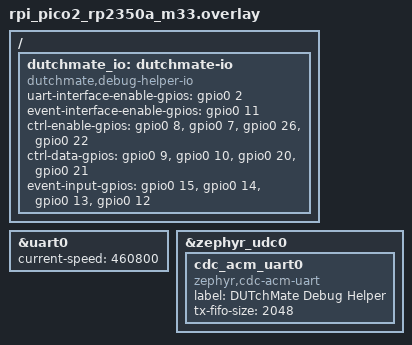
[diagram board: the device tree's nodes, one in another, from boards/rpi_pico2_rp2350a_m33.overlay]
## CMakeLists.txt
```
cmake_minimum_required(VERSION 3.20.0)

find_package(Zephyr REQUIRED HINTS $ENV{ZEPHYR_BASE})

set(DUTCHMATE_MINIMUM_ZEPHYR_VERSION "4.4.2")
set(DUTCHMATE_ZEPHYR_VERSION
    "${KERNEL_VERSION_MAJOR}.${KERNEL_VERSION_MINOR}.${KERNEL_PATCHLEVEL}"
)
if("${DUTCHMATE_ZEPHYR_VERSION}" VERSION_LESS
   "${DUTCHMATE_MINIMUM_ZEPHYR_VERSION}")
    message(FATAL_ERROR
        "DUTchMate RP2350 Debug Helper requires Zephyr "
        "${DUTCHMATE_MINIMUM_ZEPHYR_VERSION} or newer because earlier "
        "PL011 drivers do not acknowledge UART error interrupts "
        "(GHSA-36rp-2hcp-f5hv)."
    )
endif()

project(dutchmate_rp2350_debug_helper)

target_sources(app PRIVATE
    src/cdc_tx.c
    src/cdc_tx_state.c
    src/command_decode.c
    src/command_executor.c
    src/command_ingress.c
    src/command_runtime.c
    src/command_response.c
    src/connection_epoch.c
    src/control_state.c
    src/hello.c
    src/main.c
    src/ndjson_framer.c
    src/output_drain.c
    src/platform_io.c
    src/telemetry.c
    src/uart_event.c
    src/uart_rx.c
    src/uart_rx_ring.c
    src/uart_tx.c
    src/uart_tx_state.c
    src/usb_connection.c
)

target_sources_ifdef(CONFIG_DUTCHMATE_STACK_PROBE app PRIVATE
    src/stack_probe.c
)
```

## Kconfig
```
mainmenu "DUTchMate RP2350 Debug Helper"

source "Kconfig.zephyr"

config DUTCHMATE_RP2350_DEBUG_HELPER
	bool
	default y
	select PICOSDK_USE_CLAIM
	select PICOSDK_USE_TIMER

menu "DUTchMate identity"

config DUTCHMATE_FIRMWARE_VERSION
	string "Firmware product version reported by hello"
	default "development"
	help
	  Release builds use the Semantic Version from the firmware project's
	  PRODUCT_VERSION file. Development and diagnostic builds may use a 1..64 byte
	  identifier with ASCII letters, digits, dot, underscore, plus, or hyphen.

config DUTCHMATE_PRODUCTION_BUILD
	bool "Enforce production USB identity"
	help
	  Reject a build that still uses the development VID/PID pair. Production
	  builds must provide an assigned pair through CDC_ACM_SERIAL_VID and
	  CDC_ACM_SERIAL_PID.

endmenu

config DUTCHMATE_STACK_PROBE
	bool "Expose post-epoch stack high-water measurements in hello"
	depends on THREAD_ANALYZER && THREAD_NAME
	help
	  Diagnostic build only. After an epoch ends, the next hello messages
	  carry one measured thread or ISR stack each in the firmware identifier.
	  The production protocol and UART evidence remain unchanged.
```

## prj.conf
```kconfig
CONFIG_GPIO=y
CONFIG_SERIAL=y
CONFIG_UART_INTERRUPT_DRIVEN=y
CONFIG_UART_USE_RUNTIME_CONFIGURE=y

CONFIG_USB_DEVICE_STACK_NEXT=y
CONFIG_USBD_CDC_ACM_CLASS=y
CONFIG_UART_LINE_CTRL=y
CONFIG_CDC_ACM_SERIAL_INITIALIZE_AT_BOOT=y
CONFIG_CDC_ACM_SERIAL_ENABLE_AT_BOOT=y
CONFIG_CDC_ACM_SERIAL_VID=0x2E8A
CONFIG_CDC_ACM_SERIAL_PID=0x000A
CONFIG_CDC_ACM_SERIAL_MANUFACTURER_STRING="DUTchMate"
CONFIG_CDC_ACM_SERIAL_PRODUCT_STRING="Debug Helper"

CONFIG_HWINFO=y

# No console may share the future DUT UART or USB CDC transport.
CONFIG_CONSOLE=n
CONFIG_UART_CONSOLE=n
CONFIG_PRINTK=n
CONFIG_LOG=n
CONFIG_BOOT_BANNER=n

CONFIG_MINIMAL_LIBC=y
CONFIG_MAIN_STACK_SIZE=2048
CONFIG_MAIN_THREAD_PRIORITY=5
CONFIG_DUTCHMATE_FIRMWARE_VERSION="development"
```

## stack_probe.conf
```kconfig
# Opt-in USB-only runtime stack measurement image. Do not use for production.
CONFIG_THREAD_ANALYZER=y
CONFIG_THREAD_NAME=y
CONFIG_THREAD_RUNTIME_STATS=n
CONFIG_DUTCHMATE_STACK_PROBE=y
CONFIG_DUTCHMATE_FIRMWARE_VERSION="stackprobe-1"
```

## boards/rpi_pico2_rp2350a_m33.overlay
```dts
#include <zephyr/dt-bindings/gpio/gpio.h>

/ {
	dutchmate_io: dutchmate-io {
		compatible = "dutchmate,debug-helper-io";

		uart-interface-enable-gpios = <&gpio0 2 GPIO_ACTIVE_HIGH>;
		event-interface-enable-gpios = <&gpio0 11 GPIO_ACTIVE_HIGH>;

		ctrl-enable-gpios = <&gpio0 8 GPIO_ACTIVE_HIGH>,
				    <&gpio0 7 GPIO_ACTIVE_HIGH>,
				    <&gpio0 26 GPIO_ACTIVE_HIGH>,
				    <&gpio0 22 GPIO_ACTIVE_HIGH>;
		ctrl-data-gpios = <&gpio0 9 GPIO_ACTIVE_HIGH>,
				  <&gpio0 10 GPIO_ACTIVE_HIGH>,
				  <&gpio0 20 GPIO_ACTIVE_HIGH>,
				  <&gpio0 21 GPIO_ACTIVE_HIGH>;
		event-input-gpios = <&gpio0 15 GPIO_ACTIVE_HIGH>,
				    <&gpio0 14 GPIO_ACTIVE_HIGH>,
				    <&gpio0 13 GPIO_ACTIVE_HIGH>,
				    <&gpio0 12 GPIO_ACTIVE_HIGH>;
	};
};

&uart0 {
	current-speed = <460800>;
	status = "okay";
};

&zephyr_udc0 {
	cdc_acm_uart0: cdc_acm_uart0 {
		compatible = "zephyr,cdc-acm-uart";
		label = "DUTchMate Debug Helper";
		tx-fifo-size = <2048>;
	};
};
```

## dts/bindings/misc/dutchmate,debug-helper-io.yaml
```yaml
description: DUTchMate Revision A Debug Helper GPIO assignment

compatible: "dutchmate,debug-helper-io"

properties:
  uart-interface-enable-gpios:
    type: phandle-array
    required: true
    description: Active-high TXU0202 interface enable

  event-interface-enable-gpios:
    type: phandle-array
    required: true
    description: Active-high TXU0104 event interface enable

  ctrl-enable-gpios:
    type: phandle-array
    required: true
    description: Active-high CTRL0 through CTRL3 output enables

  ctrl-data-gpios:
    type: phandle-array
    required: true
    description: CTRL0 through CTRL3 data outputs

  event-input-gpios:
    type: phandle-array
    required: true
    description: EVENT0 through EVENT3 inputs
```

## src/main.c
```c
#include "platform_io.h"
#include "uart_rx.h"
#include "uart_tx.h"
#include "usb_connection.h"

#include <zephyr/kernel.h>

int main(void)
{
	if (IS_ENABLED(CONFIG_DUTCHMATE_STACK_PROBE)) {
		(void)k_thread_name_set(k_current_get(), "main");
	}
	int result = dutchmate_platform_io_initialize_safe();

	if (result != 0) {
		return result;
	}
	result = dutchmate_uart_rx_initialize();
	if (result != 0) {
		(void)dutchmate_platform_io_force_safe();
		return result;
	}
	result = dutchmate_uart_tx_initialize();
	if (result != 0) {
		(void)dutchmate_platform_io_force_safe();
		return result;
	}

	return dutchmate_usb_connection_run();
}
```

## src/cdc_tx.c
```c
#include "cdc_tx.h"

#include "command_runtime.h"

#include <errno.h>

#include <hardware/timer.h>
#include <zephyr/device.h>
#include <zephyr/drivers/uart.h>
#include <zephyr/kernel.h>
#include <zephyr/sys/atomic.h>

#define DUTCHMATE_CDC_TX_NO_PROGRESS_TIMEOUT_US 250000ULL

static const struct device *cdc;
static struct dmh_cdc_tx tx;
static struct k_spinlock tx_lock;
static atomic_t initialized;

static int write_bytes(void *context, const uint8_t *data, size_t length)
{
	const struct device *device = context;

	return uart_fifo_fill(device, data, (int)length);
}

static void stop_writes(void *context)
{
	const struct device *device = context;

	uart_irq_tx_disable(device);
}

static void cdc_callback(
	const struct device *device,
	void *user_data
)
{
	k_spinlock_key_t key;

	ARG_UNUSED(user_data);
	key = k_spin_lock(&tx_lock);
	if (device != cdc || uart_irq_update(device) <= 0) {
		dmh_cdc_tx_driver_fault(&tx);
	} else {
		while (uart_irq_is_pending(device) > 0) {
			if (uart_irq_rx_ready(device) > 0 &&
			    !dutchmate_command_runtime_on_cdc_rx_ready(device)) {
				break;
			}
			if (uart_irq_tx_ready(device) > 0) {
				dmh_cdc_tx_on_writable(&tx, time_us_64());
			}
			if (uart_irq_update(device) <= 0) {
				dmh_cdc_tx_driver_fault(&tx);
				break;
			}
		}
	}
	k_spin_unlock(&tx_lock, key);
}

int dutchmate_cdc_tx_initialize(const struct device *cdc_device)
{
	const struct dmh_cdc_tx_port port = {
		.context = (void *)cdc_device,
		.write = write_bytes,
		.stop = stop_writes,
	};
	int result;

	if (cdc_device == NULL || !device_is_ready(cdc_device) ||
	    !atomic_cas(&initialized, 0, 1)) {
		return -EINVAL;
	}
	cdc = cdc_device;
	dmh_cdc_tx_init(&tx, &port);
	result = uart_irq_callback_user_data_set(cdc, cdc_callback, NULL);
	if (result != 0) {
		atomic_clear(&initialized);
		cdc = NULL;
		return result;
	}
	return 0;
}

enum dmh_cdc_tx_result dutchmate_cdc_tx_start(
	const uint8_t *frame,
	size_t length
)
{
	enum dmh_cdc_tx_result result;
	k_spinlock_key_t key;

	if (atomic_get(&initialized) == 0) {
		return DMH_CDC_TX_HARDWARE_FAULT;
	}
	key = k_spin_lock(&tx_lock);
	result = dmh_cdc_tx_start(
		&tx,
		frame,
		length,
		time_us_64(),
		DUTCHMATE_CDC_TX_NO_PROGRESS_TIMEOUT_US
	);
	k_spin_unlock(&tx_lock, key);
	if (result == DMH_CDC_TX_PENDING) {
		uart_irq_tx_enable(cdc);
	}
	return result;
}

enum dmh_cdc_tx_result dutchmate_cdc_tx_poll(void)
{
	enum dmh_cdc_tx_result result;
	k_spinlock_key_t key;

	key = k_spin_lock(&tx_lock);
	result = dmh_cdc_tx_poll(&tx, time_us_64());
	k_spin_unlock(&tx_lock, key);
	return result;
}

void dutchmate_cdc_tx_cancel(void)
{
	k_spinlock_key_t key;

	if (atomic_get(&initialized) == 0) {
		return;
	}
	key = k_spin_lock(&tx_lock);
	dmh_cdc_tx_cancel(&tx);
	k_spin_unlock(&tx_lock, key);
}
```

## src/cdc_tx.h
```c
#ifndef DUTCHMATE_CDC_TX_H
#define DUTCHMATE_CDC_TX_H

#include "cdc_tx_state.h"

#include <stddef.h>
#include <stdint.h>

struct device;

int dutchmate_cdc_tx_initialize(const struct device *cdc_device);
enum dmh_cdc_tx_result dutchmate_cdc_tx_start(
	const uint8_t *frame,
	size_t length
);
enum dmh_cdc_tx_result dutchmate_cdc_tx_poll(void);
void dutchmate_cdc_tx_cancel(void);

#endif
```

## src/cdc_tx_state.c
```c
#include "cdc_tx_state.h"

#include <string.h>

static void finish(
	struct dmh_cdc_tx *tx,
	enum dmh_cdc_tx_result result
)
{
	tx->port.stop(tx->port.context);
	tx->state = result;
}

void dmh_cdc_tx_init(
	struct dmh_cdc_tx *tx,
	const struct dmh_cdc_tx_port *port
)
{
	tx->port = *port;
	tx->length = 0U;
	tx->accepted = 0U;
	tx->last_progress_us = 0U;
	tx->timeout_us = 0U;
	tx->state = DMH_CDC_TX_IDLE;
}

enum dmh_cdc_tx_result dmh_cdc_tx_start(
	struct dmh_cdc_tx *tx,
	const uint8_t *frame,
	size_t length,
	uint64_t now_us,
	uint64_t timeout_us
)
{
	if (frame == NULL || length == 0U || length > DMH_CDC_TX_MAX_FRAME_BYTES ||
	    timeout_us == 0U) {
		return DMH_CDC_TX_INVALID_ARGUMENT;
	}
	if (tx->state != DMH_CDC_TX_IDLE) {
		return DMH_CDC_TX_BUSY;
	}
	(void)memcpy(tx->frame, frame, length);
	tx->length = length;
	tx->accepted = 0U;
	tx->last_progress_us = now_us;
	tx->timeout_us = timeout_us;
	tx->state = DMH_CDC_TX_PENDING;
	return DMH_CDC_TX_PENDING;
}

void dmh_cdc_tx_on_writable(struct dmh_cdc_tx *tx, uint64_t now_us)
{
	size_t remaining;
	int written;

	if (tx->state != DMH_CDC_TX_PENDING) {
		tx->port.stop(tx->port.context);
		return;
	}
	remaining = tx->length - tx->accepted;
	written = tx->port.write(
		tx->port.context,
		&tx->frame[tx->accepted],
		remaining
	);
	if (written <= 0 || (size_t)written > remaining) {
		finish(tx, DMH_CDC_TX_HARDWARE_FAULT);
		return;
	}
	tx->accepted += (size_t)written;
	tx->last_progress_us = now_us;
	if (tx->accepted == tx->length) {
		finish(tx, DMH_CDC_TX_COMPLETED);
	}
}

void dmh_cdc_tx_driver_fault(struct dmh_cdc_tx *tx)
{
	if (tx->state == DMH_CDC_TX_PENDING) {
		finish(tx, DMH_CDC_TX_HARDWARE_FAULT);
	}
}

void dmh_cdc_tx_cancel(struct dmh_cdc_tx *tx)
{
	if (tx->state == DMH_CDC_TX_PENDING) {
		tx->port.stop(tx->port.context);
	}
	tx->length = 0U;
	tx->accepted = 0U;
	tx->last_progress_us = 0U;
	tx->timeout_us = 0U;
	tx->state = DMH_CDC_TX_IDLE;
}

enum dmh_cdc_tx_result dmh_cdc_tx_poll(
	struct dmh_cdc_tx *tx,
	uint64_t now_us
)
{
	enum dmh_cdc_tx_result result;

	if (tx->state == DMH_CDC_TX_PENDING &&
	    now_us - tx->last_progress_us >= tx->timeout_us) {
		finish(tx, DMH_CDC_TX_TIMEOUT);
	}
	result = tx->state;
	if (result == DMH_CDC_TX_COMPLETED ||
	    result == DMH_CDC_TX_TIMEOUT ||
	    result == DMH_CDC_TX_HARDWARE_FAULT) {
		tx->length = 0U;
		tx->accepted = 0U;
		tx->last_progress_us = 0U;
		tx->timeout_us = 0U;
		tx->state = DMH_CDC_TX_IDLE;
	}
	return result;
}
```

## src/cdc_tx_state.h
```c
#ifndef DUTCHMATE_CDC_TX_STATE_H
#define DUTCHMATE_CDC_TX_STATE_H

#include <stddef.h>
#include <stdint.h>

#define DMH_CDC_TX_MAX_FRAME_BYTES 1536U

enum dmh_cdc_tx_result {
	DMH_CDC_TX_IDLE = 0,
	DMH_CDC_TX_PENDING,
	DMH_CDC_TX_COMPLETED,
	DMH_CDC_TX_INVALID_ARGUMENT,
	DMH_CDC_TX_BUSY,
	DMH_CDC_TX_TIMEOUT,
	DMH_CDC_TX_HARDWARE_FAULT,
};

struct dmh_cdc_tx_port {
	void *context;
	int (*write)(void *context, const uint8_t *data, size_t length);
	void (*stop)(void *context);
};

struct dmh_cdc_tx {
	struct dmh_cdc_tx_port port;
	uint8_t frame[DMH_CDC_TX_MAX_FRAME_BYTES];
	size_t length;
	size_t accepted;
	uint64_t last_progress_us;
	uint64_t timeout_us;
	enum dmh_cdc_tx_result state;
};

void dmh_cdc_tx_init(
	struct dmh_cdc_tx *tx,
	const struct dmh_cdc_tx_port *port
);
enum dmh_cdc_tx_result dmh_cdc_tx_start(
	struct dmh_cdc_tx *tx,
	const uint8_t *frame,
	size_t length,
	uint64_t now_us,
	uint64_t timeout_us
);
void dmh_cdc_tx_on_writable(struct dmh_cdc_tx *tx, uint64_t now_us);
void dmh_cdc_tx_driver_fault(struct dmh_cdc_tx *tx);
void dmh_cdc_tx_cancel(struct dmh_cdc_tx *tx);
enum dmh_cdc_tx_result dmh_cdc_tx_poll(
	struct dmh_cdc_tx *tx,
	uint64_t now_us
);

#endif
```

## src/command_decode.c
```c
#include "command_decode.h"

#include <errno.h>
#include <limits.h>
#include <string.h>

#define DMH_COMMAND_FRAME_MAX_BODY_BYTES 2047U
#define DMH_COMMAND_NAME_MAX_BYTES 23U
#define DMH_BASE64_MAX_BYTES 1368U

enum field_id {
	FIELD_CMD = 0,
	FIELD_CHANNEL,
	FIELD_MODE,
	FIELD_ACTIVE_LEVEL,
	FIELD_IDLE_LEVEL,
	FIELD_PULSE_MS,
	FIELD_STATE,
	FIELD_DATA_B64,
	FIELD_COUNT,
};

enum string_parse_result {
	STRING_PARSE_OK = 0,
	STRING_PARSE_SYNTAX,
	STRING_PARSE_LIMIT,
};

struct parser {
	const uint8_t *data;
	size_t length;
	size_t index;
};

struct raw_fields {
	uint32_t present;
	char cmd[DMH_COMMAND_NAME_MAX_BYTES + 1U];
	char channel[6];
	char mode[11];
	char active_level[5];
	char idle_level[5];
	char state[7];
	char data_b64[DMH_BASE64_MAX_BYTES + 1U];
	uint32_t pulse_ms;
};

static void skip_whitespace(struct parser *parser)
{
	while (parser->index < parser->length &&
	       (parser->data[parser->index] == ' ' ||
		parser->data[parser->index] == '\t')) {
		parser->index++;
	}
}

static int hex_value(uint8_t byte)
{
	if (byte >= '0' && byte <= '9') {
		return byte - '0';
	}
	if (byte >= 'a' && byte <= 'f') {
		return byte - 'a' + 10;
	}
	if (byte >= 'A' && byte <= 'F') {
		return byte - 'A' + 10;
	}
	return -1;
}

static enum string_parse_result append_string_byte(
	char *output,
	size_t output_capacity,
	size_t *output_length,
	uint8_t byte
)
{
	if (byte == 0U || *output_length + 1U >= output_capacity) {
		return STRING_PARSE_LIMIT;
	}
	output[*output_length] = (char)byte;
	(*output_length)++;
	return STRING_PARSE_OK;
}

static enum string_parse_result parse_unicode_escape(
	struct parser *parser,
	char *output,
	size_t output_capacity,
	size_t *output_length
)
{
	unsigned int codepoint = 0U;
	size_t count;

	if (parser->length - parser->index < 4U) {
		return STRING_PARSE_SYNTAX;
	}
	for (count = 0U; count < 4U; count++) {
		int digit = hex_value(parser->data[parser->index++]);

		if (digit < 0) {
			return STRING_PARSE_SYNTAX;
		}
		codepoint = (codepoint << 4U) | (unsigned int)digit;
	}
	if (codepoint > 0x7FU) {
		return STRING_PARSE_LIMIT;
	}
	return append_string_byte(
		output,
		output_capacity,
		output_length,
		(uint8_t)codepoint
	);
}

static enum string_parse_result parse_json_string(
	struct parser *parser,
	char *output,
	size_t output_capacity
)
{
	size_t output_length = 0U;

	if (parser->index >= parser->length || parser->data[parser->index] != '"') {
		return STRING_PARSE_SYNTAX;
	}
	parser->index++;
	while (parser->index < parser->length) {
		uint8_t byte = parser->data[parser->index++];
		enum string_parse_result result;

		if (byte == '"') {
			output[output_length] = '\0';
			return STRING_PARSE_OK;
		}
		if (byte < 0x20U || byte >= 0x80U) {
			return STRING_PARSE_SYNTAX;
		}
		if (byte != '\\') {
			result = append_string_byte(
				output, output_capacity, &output_length, byte
			);
		} else {
			if (parser->index >= parser->length) {
				return STRING_PARSE_SYNTAX;
			}
			byte = parser->data[parser->index++];
			if (byte == 'u') {
				result = parse_unicode_escape(
					parser,
					output,
					output_capacity,
					&output_length
				);
			} else {
				switch (byte) {
				case '"':
				case '\\':
				case '/':
					break;
				case 'b':
					byte = '\b';
					break;
				case 'f':
					byte = '\f';
					break;
				case 'n':
					byte = '\n';
					break;
				case 'r':
					byte = '\r';
					break;
				case 't':
					byte = '\t';
					break;
				default:
					return STRING_PARSE_SYNTAX;
				}
				result = append_string_byte(
					output, output_capacity, &output_length, byte
				);
			}
		}
		if (result != STRING_PARSE_OK) {
			return result;
		}
	}
	return STRING_PARSE_SYNTAX;
}

static int field_id_from_name(const char *name)
{
	static const char *const names[] = {
		[FIELD_CMD] = "cmd",
		[FIELD_CHANNEL] = "channel",
		[FIELD_MODE] = "mode",
		[FIELD_ACTIVE_LEVEL] = "active_level",
		[FIELD_IDLE_LEVEL] = "idle_level",
		[FIELD_PULSE_MS] = "pulse_ms",
		[FIELD_STATE] = "state",
		[FIELD_DATA_B64] = "data_b64",
	};
	size_t index;

	for (index = 0U; index < FIELD_COUNT; index++) {
		if (strcmp(name, names[index]) == 0) {
			return (int)index;
		}
	}
	return -1;
}

static enum string_parse_result parse_field_string(
	struct parser *parser,
	struct raw_fields *fields,
	enum field_id field
)
{
	switch (field) {
	case FIELD_CMD:
		return parse_json_string(parser, fields->cmd, sizeof(fields->cmd));
	case FIELD_CHANNEL:
		return parse_json_string(
			parser, fields->channel, sizeof(fields->channel)
		);
	case FIELD_MODE:
		return parse_json_string(parser, fields->mode, sizeof(fields->mode));
	case FIELD_ACTIVE_LEVEL:
		return parse_json_string(
			parser, fields->active_level, sizeof(fields->active_level)
		);
	case FIELD_IDLE_LEVEL:
		return parse_json_string(
			parser, fields->idle_level, sizeof(fields->idle_level)
		);
	case FIELD_STATE:
		return parse_json_string(parser, fields->state, sizeof(fields->state));
	case FIELD_DATA_B64:
		return parse_json_string(
			parser, fields->data_b64, sizeof(fields->data_b64)
		);
	case FIELD_PULSE_MS:
	case FIELD_COUNT:
		return STRING_PARSE_SYNTAX;
	}
	return STRING_PARSE_SYNTAX;
}

static bool parse_pulse_ms(struct parser *parser, uint32_t *value)
{
	uint32_t parsed = 0U;
	size_t start = parser->index;

	if (start >= parser->length || parser->data[start] < '0' ||
	    parser->data[start] > '9') {
		return false;
	}
	if (parser->data[start] == '0' && start + 1U < parser->length &&
	    parser->data[start + 1U] >= '0' && parser->data[start + 1U] <= '9') {
		return false;
	}
	while (parser->index < parser->length &&
	       parser->data[parser->index] >= '0' &&
	       parser->data[parser->index] <= '9') {
		uint32_t digit = parser->data[parser->index] - '0';

		if (parsed > (UINT32_MAX - digit) / 10U) {
			return false;
		}
		parsed = parsed * 10U + digit;
		parser->index++;
	}
	*value = parsed;
	return true;
}

static int parse_object(
	const uint8_t *frame,
	size_t frame_length,
	struct raw_fields *fields,
	enum dmh_command_decode_failure *failure
)
{
	struct parser parser = {
		.data = frame,
		.length = frame_length,
		.index = 1U,
	};

	if (frame_length < 2U || frame[0] != '{' || frame[frame_length - 1U] != '}') {
		*failure = DMH_COMMAND_DECODE_INVALID_COMMAND;
		return -EINVAL;
	}
	for (;;) {
		char key[17];
		enum string_parse_result string_result;
		int field_number;
		enum field_id field;

		skip_whitespace(&parser);
		if (parser.index >= parser.length) {
			*failure = DMH_COMMAND_DECODE_INVALID_COMMAND;
			return -EINVAL;
		}
		if (parser.data[parser.index] == '}') {
			parser.index++;
			break;
		}
		string_result = parse_json_string(&parser, key, sizeof(key));
		if (string_result != STRING_PARSE_OK) {
			*failure = string_result == STRING_PARSE_LIMIT ?
				DMH_COMMAND_DECODE_INVALID_ARGUMENT :
				DMH_COMMAND_DECODE_INVALID_COMMAND;
			return -EINVAL;
		}
		field_number = field_id_from_name(key);
		if (field_number < 0) {
			*failure = DMH_COMMAND_DECODE_INVALID_ARGUMENT;
			return -EINVAL;
		}
		field = (enum field_id)field_number;
		if ((fields->present & (1U << field)) != 0U) {
			*failure = DMH_COMMAND_DECODE_INVALID_ARGUMENT;
			return -EINVAL;
		}
		skip_whitespace(&parser);
		if (parser.index >= parser.length || parser.data[parser.index] != ':') {
			*failure = DMH_COMMAND_DECODE_INVALID_COMMAND;
			return -EINVAL;
		}
		parser.index++;
		skip_whitespace(&parser);
		if (field == FIELD_PULSE_MS) {
			if (!parse_pulse_ms(&parser, &fields->pulse_ms)) {
				*failure = DMH_COMMAND_DECODE_INVALID_ARGUMENT;
				return -EINVAL;
			}
		} else {
			if (parser.index >= parser.length ||
			    parser.data[parser.index] != '"') {
				*failure = field == FIELD_CMD ?
					DMH_COMMAND_DECODE_INVALID_COMMAND :
					DMH_COMMAND_DECODE_INVALID_ARGUMENT;
				return -EINVAL;
			}
			string_result = parse_field_string(&parser, fields, field);
			if (string_result != STRING_PARSE_OK) {
				*failure = string_result == STRING_PARSE_SYNTAX ?
					DMH_COMMAND_DECODE_INVALID_COMMAND :
					DMH_COMMAND_DECODE_INVALID_ARGUMENT;
				return -EINVAL;
			}
		}
		fields->present |= 1U << field;
		skip_whitespace(&parser);
		if (parser.index >= parser.length) {
			*failure = DMH_COMMAND_DECODE_INVALID_COMMAND;
			return -EINVAL;
		}
		if (parser.data[parser.index] == '}') {
			parser.index++;
			break;
		}
		if (parser.data[parser.index] != ',') {
			*failure = DMH_COMMAND_DECODE_INVALID_COMMAND;
			return -EINVAL;
		}
		parser.index++;
		skip_whitespace(&parser);
		if (parser.index >= parser.length || parser.data[parser.index] == '}') {
			*failure = DMH_COMMAND_DECODE_INVALID_COMMAND;
			return -EINVAL;
		}
	}
	if (parser.index != parser.length) {
		*failure = DMH_COMMAND_DECODE_INVALID_COMMAND;
		return -EINVAL;
	}
	return 0;
}

static bool decode_channel(const char *value, uint8_t *channel)
{
	if (strlen(value) != 5U || memcmp(value, "CTRL", 4U) != 0 ||
	    value[4] < '0' || value[4] > '3') {
		return false;
	}
	*channel = (uint8_t)(value[4] - '0');
	return true;
}

static bool decode_level(const char *value, enum dmh_control_level *level)
{
	if (strcmp(value, "low") == 0) {
		*level = DMH_CONTROL_LEVEL_LOW;
		return true;
	}
	if (strcmp(value, "high") == 0) {
		*level = DMH_CONTROL_LEVEL_HIGH;
		return true;
	}
	return false;
}

static int base64_value(char byte)
{
	if (byte >= 'A' && byte <= 'Z') {
		return byte - 'A';
	}
	if (byte >= 'a' && byte <= 'z') {
		return byte - 'a' + 26;
	}
	if (byte >= '0' && byte <= '9') {
		return byte - '0' + 52;
	}
	if (byte == '+') {
		return 62;
	}
	if (byte == '/') {
		return 63;
	}
	return -1;
}

static bool decode_base64(const char *encoded, struct dmh_uart_send_command *uart)
{
	size_t encoded_length = strlen(encoded);
	size_t input_index;
	size_t output_index = 0U;

	if (encoded_length < 4U || encoded_length > DMH_BASE64_MAX_BYTES ||
	    encoded_length % 4U != 0U) {
		return false;
	}
	for (input_index = 0U; input_index < encoded_length; input_index += 4U) {
		int first = base64_value(encoded[input_index]);
		int second = base64_value(encoded[input_index + 1U]);
		int third;
		int fourth;
		bool last = input_index + 4U == encoded_length;

		if (first < 0 || second < 0 || output_index >= sizeof(uart->data)) {
			return false;
		}
		uart->data[output_index++] =
			(uint8_t)(((unsigned int)first << 2U) |
				 ((unsigned int)second >> 4U));
		if (encoded[input_index + 2U] == '=') {
			if (!last || encoded[input_index + 3U] != '=') {
				return false;
			}
			continue;
		}
		third = base64_value(encoded[input_index + 2U]);
		if (third < 0 || output_index >= sizeof(uart->data)) {
			return false;
		}
		uart->data[output_index++] =
			(uint8_t)(((unsigned int)second << 4U) |
				 ((unsigned int)third >> 2U));
		if (encoded[input_index + 3U] == '=') {
			if (!last) {
				return false;
			}
			continue;
		}
		fourth = base64_value(encoded[input_index + 3U]);
		if (fourth < 0 || output_index >= sizeof(uart->data)) {
			return false;
		}
		uart->data[output_index++] =
			(uint8_t)(((unsigned int)third << 6U) | (unsigned int)fourth);
	}
	uart->length = output_index;
	return output_index > 0U;
}

static bool exact_fields(uint32_t actual, uint32_t required)
{
	return actual == required;
}

static bool decode_configure(
	const struct raw_fields *fields,
	struct dmh_command *command
)
{
	uint32_t required = (1U << FIELD_CMD) | (1U << FIELD_CHANNEL) |
			    (1U << FIELD_MODE) | (1U << FIELD_ACTIVE_LEVEL);
	struct dmh_configure_command *configure = &command->value.configure;

	if (!decode_channel(fields->channel, &command->channel) ||
	    !decode_level(fields->active_level, &configure->active_level)) {
		return false;
	}
	if (strcmp(fields->mode, "open_drain") == 0) {
		if (!exact_fields(fields->present, required) ||
		    configure->active_level != DMH_CONTROL_LEVEL_LOW) {
			return false;
		}
		configure->mode = DMH_CONTROL_MODE_OPEN_DRAIN;
		configure->has_idle_level = false;
	} else if (strcmp(fields->mode, "push_pull") == 0) {
		required |= 1U << FIELD_IDLE_LEVEL;
		if (!exact_fields(fields->present, required) ||
		    !decode_level(fields->idle_level, &configure->idle_level) ||
		    configure->active_level == configure->idle_level) {
			return false;
		}
		configure->mode = DMH_CONTROL_MODE_PUSH_PULL;
		configure->has_idle_level = true;
	} else {
		return false;
	}
	command->kind = DMH_COMMAND_CONFIGURE_GPIO_MODE;
	return true;
}

static bool decode_pulse(
	const struct raw_fields *fields,
	struct dmh_command *command
)
{
	uint32_t required = (1U << FIELD_CMD) | (1U << FIELD_CHANNEL) |
			    (1U << FIELD_PULSE_MS);

	if (!exact_fields(fields->present, required) || fields->pulse_ms < 1U ||
	    fields->pulse_ms > 10000U ||
	    !decode_channel(fields->channel, &command->channel)) {
		return false;
	}
	command->kind = DMH_COMMAND_PULSE_CONTROL;
	command->value.pulse_ms = fields->pulse_ms;
	return true;
}

static bool decode_state(
	const struct raw_fields *fields,
	struct dmh_command *command
)
{
	uint32_t required = (1U << FIELD_CMD) | (1U << FIELD_CHANNEL) |
			    (1U << FIELD_STATE);

	if (!exact_fields(fields->present, required) ||
	    !decode_channel(fields->channel, &command->channel)) {
		return false;
	}
	if (strcmp(fields->state, "active") == 0) {
		command->value.control_state = DMH_CONTROL_STATE_ACTIVE;
	} else if (strcmp(fields->state, "idle") == 0) {
		command->value.control_state = DMH_CONTROL_STATE_IDLE;
	} else {
		return false;
	}
	command->kind = DMH_COMMAND_SET_CONTROL_STATE;
	return true;
}

static bool decode_uart_send(
	const struct raw_fields *fields,
	struct dmh_command *command
)
{
	uint32_t required = (1U << FIELD_CMD) | (1U << FIELD_DATA_B64);

	if (!exact_fields(fields->present, required) ||
	    !decode_base64(fields->data_b64, &command->value.uart_send)) {
		return false;
	}
	command->kind = DMH_COMMAND_UART_SEND;
	return true;
}

int dmh_command_decode(
	const uint8_t *frame,
	size_t frame_length,
	struct dmh_command *command,
	enum dmh_command_decode_failure *failure
)
{
	struct raw_fields fields = {0};
	bool valid;

	if ((frame == NULL && frame_length > 0U) || command == NULL ||
	    failure == NULL) {
		return -EINVAL;
	}
	memset(command, 0, sizeof(*command));
	if (frame_length == 0U || frame_length > DMH_COMMAND_FRAME_MAX_BODY_BYTES ||
	    parse_object(frame, frame_length, &fields, failure) != 0) {
		if (frame_length == 0U || frame_length > DMH_COMMAND_FRAME_MAX_BODY_BYTES) {
			*failure = DMH_COMMAND_DECODE_INVALID_COMMAND;
		}
		return -EINVAL;
	}
	if ((fields.present & (1U << FIELD_CMD)) == 0U || fields.cmd[0] == '\0') {
		*failure = DMH_COMMAND_DECODE_INVALID_COMMAND;
		return -EINVAL;
	}
	if (strcmp(fields.cmd, "configure_gpio_mode") == 0) {
		valid = decode_configure(&fields, command);
	} else if (strcmp(fields.cmd, "pulse_control") == 0) {
		valid = decode_pulse(&fields, command);
	} else if (strcmp(fields.cmd, "set_control_state") == 0) {
		valid = decode_state(&fields, command);
	} else if (strcmp(fields.cmd, "uart_send") == 0) {
		valid = decode_uart_send(&fields, command);
	} else {
		*failure = DMH_COMMAND_DECODE_INVALID_COMMAND;
		return -EINVAL;
	}
	if (!valid) {
		memset(command, 0, sizeof(*command));
		*failure = DMH_COMMAND_DECODE_INVALID_ARGUMENT;
		return -EINVAL;
	}
	return 0;
}
```

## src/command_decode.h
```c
#ifndef DUTCHMATE_COMMAND_DECODE_H
#define DUTCHMATE_COMMAND_DECODE_H

#include "control_types.h"
#include "uart_limits.h"

#include <stdbool.h>
#include <stddef.h>
#include <stdint.h>

enum dmh_command_kind {
	DMH_COMMAND_NONE = 0,
	DMH_COMMAND_CONFIGURE_GPIO_MODE,
	DMH_COMMAND_PULSE_CONTROL,
	DMH_COMMAND_SET_CONTROL_STATE,
	DMH_COMMAND_UART_SEND,
};

enum dmh_command_decode_failure {
	DMH_COMMAND_DECODE_INVALID_COMMAND = 0,
	DMH_COMMAND_DECODE_INVALID_ARGUMENT,
};

struct dmh_configure_command {
	enum dmh_control_mode mode;
	enum dmh_control_level active_level;
	enum dmh_control_level idle_level;
	bool has_idle_level;
};

struct dmh_uart_send_command {
	uint8_t data[DMH_UART_SEND_MAX_BYTES];
	size_t length;
};

struct dmh_command {
	enum dmh_command_kind kind;
	uint8_t channel;
	union {
		struct dmh_configure_command configure;
		uint32_t pulse_ms;
		enum dmh_control_state control_state;
		struct dmh_uart_send_command uart_send;
	} value;
};

int dmh_command_decode(
	const uint8_t *frame,
	size_t frame_length,
	struct dmh_command *command,
	enum dmh_command_decode_failure *failure
);

#endif
```

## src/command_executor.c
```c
#include "command_executor.h"

#include <string.h>

static const char invalid_command_detail[] = "Command is invalid";
static const char invalid_argument_detail[] = "Command argument is invalid";
static const char control_fault_detail[] = "Control hardware operation failed";
static const char uart_fault_detail[] = "UART transmission failed";
static const char uart_timeout_detail[] = "UART transmission timed out";

static enum dmh_command_executor_result response_encoded(
	struct dmh_command_executor *executor,
	int encode_result
)
{
	if (encode_result != 0) {
		executor->state = DMH_COMMAND_EXECUTOR_STATE_IDLE;
		executor->response_length = 0U;
		return DMH_COMMAND_EXECUTOR_INTERNAL_FAULT;
	}
	executor->state = DMH_COMMAND_EXECUTOR_STATE_RESPONSE;
	return DMH_COMMAND_EXECUTOR_RESPONSE_READY;
}

static enum dmh_command_executor_result stage_timestamp(
	struct dmh_command_executor *executor,
	uint64_t timestamp_us
)
{
	return response_encoded(
		executor,
		dmh_timestamp_response_encode(
			timestamp_us,
			executor->response,
			sizeof(executor->response),
			&executor->response_length
		)
	);
}

static enum dmh_command_executor_result stage_uart_success(
	struct dmh_command_executor *executor,
	uint64_t timestamp_us,
	size_t bytes_accepted
)
{
	return response_encoded(
		executor,
		dmh_uart_send_response_encode(
			timestamp_us,
			bytes_accepted,
			executor->response,
			sizeof(executor->response),
			&executor->response_length
		)
	);
}

static enum dmh_command_executor_result stage_error(
	struct dmh_command_executor *executor,
	enum dmh_command_error_code code,
	const char *detail,
	size_t detail_length
)
{
	return response_encoded(
		executor,
		dmh_error_response_encode(
			code,
			detail,
			detail_length,
			executor->response,
			sizeof(executor->response),
			&executor->response_length
		)
	);
}

static enum dmh_command_executor_result stage_literal_error(
	struct dmh_command_executor *executor,
	enum dmh_command_error_code code,
	const char *detail
)
{
	return stage_error(executor, code, detail, strlen(detail));
}

static enum dmh_command_executor_result stage_not_configured(
	struct dmh_command_executor *executor,
	uint8_t channel
)
{
	char detail[] = "CTRL0 is not configured";

	detail[4] = (char)('0' + channel);
	return stage_error(
		executor,
		DMH_COMMAND_ERROR_NOT_CONFIGURED,
		detail,
		sizeof(detail) - 1U
	);
}

static enum dmh_command_executor_result map_control_result(
	struct dmh_command_executor *executor,
	enum dmh_control_result result,
	uint8_t channel,
	uint64_t timestamp_us
)
{
	if (result == DMH_CONTROL_OK) {
		return stage_timestamp(executor, timestamp_us);
	}
	if (result == DMH_CONTROL_INVALID_ARGUMENT) {
		return stage_literal_error(
			executor,
			DMH_COMMAND_ERROR_INVALID_ARGUMENT,
			invalid_argument_detail
		);
	}
	if (result == DMH_CONTROL_NOT_CONFIGURED) {
		return stage_not_configured(executor, channel);
	}
	return stage_literal_error(
		executor,
		DMH_COMMAND_ERROR_HARDWARE_FAULT,
		control_fault_detail
	);
}

static enum dmh_command_executor_result submit_configure(
	struct dmh_command_executor *executor,
	const struct dmh_command *command,
	uint64_t now_us
)
{
	const struct dmh_configure_command *configuration = &command->value.configure;

	return map_control_result(
		executor,
		dmh_control_configure(
			executor->control,
			command->channel,
			configuration->mode,
			configuration->active_level,
			configuration->has_idle_level,
			configuration->idle_level
		),
		command->channel,
		now_us
	);
}

static enum dmh_command_executor_result submit_pulse(
	struct dmh_command_executor *executor,
	const struct dmh_command *command,
	uint64_t now_us
)
{
	enum dmh_control_result result = dmh_control_pulse_start(
		executor->control,
		command->channel,
		command->value.pulse_ms,
		now_us
	);

	if (result == DMH_CONTROL_PENDING) {
		executor->state = DMH_COMMAND_EXECUTOR_STATE_CONTROL_PULSE;
		return DMH_COMMAND_EXECUTOR_PENDING;
	}
	return map_control_result(executor, result, command->channel, now_us);
}

static enum dmh_command_executor_result submit_control_state(
	struct dmh_command_executor *executor,
	const struct dmh_command *command,
	uint64_t now_us
)
{
	return map_control_result(
		executor,
		dmh_control_set_state(
			executor->control,
			command->channel,
			command->value.control_state
		),
		command->channel,
		now_us
	);
}

static enum dmh_command_executor_result submit_uart(
	struct dmh_command_executor *executor,
	const struct dmh_command *command,
	uint64_t now_us
)
{
	enum dmh_uart_tx_result result = executor->uart.start(
		executor->uart.context,
		command->value.uart_send.data,
		command->value.uart_send.length,
		now_us
	);

	if (result == DMH_UART_TX_PENDING) {
		executor->state = DMH_COMMAND_EXECUTOR_STATE_UART_TX;
		return DMH_COMMAND_EXECUTOR_PENDING;
	}
	if (result == DMH_UART_TX_COMPLETED) {
		return stage_uart_success(
			executor,
			now_us,
			command->value.uart_send.length
		);
	}
	if (result == DMH_UART_TX_INVALID_ARGUMENT) {
		return stage_literal_error(
			executor,
			DMH_COMMAND_ERROR_INVALID_ARGUMENT,
			invalid_argument_detail
		);
	}
	return stage_literal_error(
		executor,
		DMH_COMMAND_ERROR_HARDWARE_FAULT,
		uart_fault_detail
	);
}

void dmh_command_executor_init(
	struct dmh_command_executor *executor,
	struct dmh_control *control,
	const struct dmh_command_uart_port *uart
)
{
	executor->control = control;
	executor->uart = *uart;
	executor->state = DMH_COMMAND_EXECUTOR_STATE_IDLE;
	executor->response_length = 0U;
}

enum dmh_command_executor_result dmh_command_executor_submit(
	struct dmh_command_executor *executor,
	const struct dmh_command *command,
	uint64_t now_us
)
{
	if (executor->state != DMH_COMMAND_EXECUTOR_STATE_IDLE) {
		return DMH_COMMAND_EXECUTOR_BUSY;
	}
	if (command->kind == DMH_COMMAND_CONFIGURE_GPIO_MODE) {
		return submit_configure(executor, command, now_us);
	}
	if (command->kind == DMH_COMMAND_PULSE_CONTROL) {
		return submit_pulse(executor, command, now_us);
	}
	if (command->kind == DMH_COMMAND_SET_CONTROL_STATE) {
		return submit_control_state(executor, command, now_us);
	}
	if (command->kind == DMH_COMMAND_UART_SEND) {
		return submit_uart(executor, command, now_us);
	}
	return stage_literal_error(
		executor,
		DMH_COMMAND_ERROR_INVALID_COMMAND,
		invalid_command_detail
	);
}

enum dmh_command_executor_result dmh_command_executor_reject(
	struct dmh_command_executor *executor,
	enum dmh_command_decode_failure failure
)
{
	if (executor->state != DMH_COMMAND_EXECUTOR_STATE_IDLE) {
		return DMH_COMMAND_EXECUTOR_BUSY;
	}
	if (failure == DMH_COMMAND_DECODE_INVALID_ARGUMENT) {
		return stage_literal_error(
			executor,
			DMH_COMMAND_ERROR_INVALID_ARGUMENT,
			invalid_argument_detail
		);
	}
	return stage_literal_error(
		executor,
		DMH_COMMAND_ERROR_INVALID_COMMAND,
		invalid_command_detail
	);
}

enum dmh_command_executor_result dmh_command_executor_poll(
	struct dmh_command_executor *executor,
	uint64_t now_us
)
{
	if (executor->state == DMH_COMMAND_EXECUTOR_STATE_CONTROL_PULSE) {
		enum dmh_control_poll_result result = dmh_control_poll(
			executor->control,
			now_us
		);

		if (result == DMH_CONTROL_POLL_COMPLETED) {
			return stage_timestamp(executor, now_us);
		}
		if (result == DMH_CONTROL_POLL_HARDWARE_FAULT) {
			return stage_literal_error(
				executor,
				DMH_COMMAND_ERROR_HARDWARE_FAULT,
				control_fault_detail
			);
		}
		return DMH_COMMAND_EXECUTOR_PENDING;
	}
	if (executor->state == DMH_COMMAND_EXECUTOR_STATE_UART_TX) {
		size_t bytes_accepted;
		enum dmh_uart_tx_result result = executor->uart.poll(
			executor->uart.context,
			now_us,
			&bytes_accepted
		);

		if (result == DMH_UART_TX_COMPLETED) {
			return stage_uart_success(executor, now_us, bytes_accepted);
		}
		if (result == DMH_UART_TX_TIMEOUT) {
			return stage_literal_error(
				executor,
				DMH_COMMAND_ERROR_TIMEOUT,
				uart_timeout_detail
			);
		}
		if (result == DMH_UART_TX_HARDWARE_FAULT) {
			return stage_literal_error(
				executor,
				DMH_COMMAND_ERROR_HARDWARE_FAULT,
				uart_fault_detail
			);
		}
		if (result != DMH_UART_TX_PENDING) {
			return DMH_COMMAND_EXECUTOR_INTERNAL_FAULT;
		}
		return DMH_COMMAND_EXECUTOR_PENDING;
	}
	if (executor->state == DMH_COMMAND_EXECUTOR_STATE_RESPONSE) {
		return DMH_COMMAND_EXECUTOR_RESPONSE_READY;
	}
	return DMH_COMMAND_EXECUTOR_IDLE;
}

const char *dmh_command_executor_response(
	const struct dmh_command_executor *executor,
	size_t *response_length
)
{
	if (executor->state != DMH_COMMAND_EXECUTOR_STATE_RESPONSE) {
		*response_length = 0U;
		return NULL;
	}
	*response_length = executor->response_length;
	return executor->response;
}

void dmh_command_executor_response_sent(struct dmh_command_executor *executor)
{
	if (executor->state == DMH_COMMAND_EXECUTOR_STATE_RESPONSE) {
		executor->response_length = 0U;
		executor->state = DMH_COMMAND_EXECUTOR_STATE_IDLE;
	}
}

enum dmh_control_result dmh_command_executor_cancel_epoch(
	struct dmh_command_executor *executor
)
{
	executor->uart.cancel(executor->uart.context);
	executor->state = DMH_COMMAND_EXECUTOR_STATE_IDLE;
	executor->response_length = 0U;
	return dmh_control_end_epoch(executor->control);
}
```

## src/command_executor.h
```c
#ifndef DUTCHMATE_COMMAND_EXECUTOR_H
#define DUTCHMATE_COMMAND_EXECUTOR_H

#include "command_decode.h"
#include "command_response.h"
#include "control_state.h"
#include "uart_tx_state.h"

#include <stddef.h>
#include <stdint.h>

enum dmh_command_executor_result {
	DMH_COMMAND_EXECUTOR_IDLE = 0,
	DMH_COMMAND_EXECUTOR_PENDING,
	DMH_COMMAND_EXECUTOR_RESPONSE_READY,
	DMH_COMMAND_EXECUTOR_BUSY,
	DMH_COMMAND_EXECUTOR_INTERNAL_FAULT,
};

struct dmh_command_uart_port {
	void *context;
	enum dmh_uart_tx_result (*start)(
		void *context,
		const uint8_t *data,
		size_t length,
		uint64_t now_us
	);
	enum dmh_uart_tx_result (*poll)(
		void *context,
		uint64_t now_us,
		size_t *bytes_accepted
	);
	void (*cancel)(void *context);
};

enum dmh_command_executor_state {
	DMH_COMMAND_EXECUTOR_STATE_IDLE = 0,
	DMH_COMMAND_EXECUTOR_STATE_CONTROL_PULSE,
	DMH_COMMAND_EXECUTOR_STATE_UART_TX,
	DMH_COMMAND_EXECUTOR_STATE_RESPONSE,
};

struct dmh_command_executor {
	struct dmh_control *control;
	struct dmh_command_uart_port uart;
	enum dmh_command_executor_state state;
	char response[DMH_COMMAND_RESPONSE_FRAME_CAPACITY];
	size_t response_length;
};

void dmh_command_executor_init(
	struct dmh_command_executor *executor,
	struct dmh_control *control,
	const struct dmh_command_uart_port *uart
);
enum dmh_command_executor_result dmh_command_executor_submit(
	struct dmh_command_executor *executor,
	const struct dmh_command *command,
	uint64_t now_us
);
enum dmh_command_executor_result dmh_command_executor_reject(
	struct dmh_command_executor *executor,
	enum dmh_command_decode_failure failure
);
enum dmh_command_executor_result dmh_command_executor_poll(
	struct dmh_command_executor *executor,
	uint64_t now_us
);
const char *dmh_command_executor_response(
	const struct dmh_command_executor *executor,
	size_t *response_length
);
void dmh_command_executor_response_sent(struct dmh_command_executor *executor);
enum dmh_control_result dmh_command_executor_cancel_epoch(
	struct dmh_command_executor *executor
);

#endif
```

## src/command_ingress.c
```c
#include "command_ingress.h"

#include <errno.h>
#include <string.h>

void dmh_command_ingress_reset(struct dmh_command_ingress *ingress)
{
	dmh_ndjson_framer_reset(&ingress->framer);
}

void dmh_command_ingress_init(struct dmh_command_ingress *ingress)
{
	dmh_ndjson_framer_init(&ingress->framer);
}

int dmh_command_ingress_feed(
	struct dmh_command_ingress *ingress,
	const uint8_t *input,
	size_t input_length,
	struct dmh_command_request *request,
	size_t *consumed_bytes
)
{
	struct dmh_ndjson_result frame;
	enum dmh_command_decode_failure failure;
	int result;

	if (ingress == NULL || request == NULL || consumed_bytes == NULL) {
		return -EINVAL;
	}
	(void)memset(request, 0, sizeof(*request));
	result = dmh_ndjson_framer_feed(
		&ingress->framer, input, input_length, &frame
	);
	if (result != 0) {
		return result;
	}
	*consumed_bytes = frame.consumed_bytes;
	if (frame.outcome == DMH_NDJSON_INCOMPLETE) {
		return 0;
	}
	if (frame.outcome == DMH_NDJSON_FRAME_TOO_LARGE) {
		request->kind = DMH_COMMAND_REQUEST_INVALID_ARGUMENT;
		return 0;
	}
	result = dmh_command_decode(
		frame.frame,
		frame.frame_length,
		&request->command,
		&failure
	);
	if (result == 0) {
		request->kind = DMH_COMMAND_REQUEST_COMMAND;
	} else if (failure == DMH_COMMAND_DECODE_INVALID_ARGUMENT) {
		request->kind = DMH_COMMAND_REQUEST_INVALID_ARGUMENT;
	} else {
		request->kind = DMH_COMMAND_REQUEST_INVALID_COMMAND;
	}
	return 0;
}
```

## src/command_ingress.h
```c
#ifndef DUTCHMATE_COMMAND_INGRESS_H
#define DUTCHMATE_COMMAND_INGRESS_H

#include "command_decode.h"
#include "ndjson_framer.h"

#include <stddef.h>
#include <stdint.h>

enum dmh_command_request_kind {
	DMH_COMMAND_REQUEST_NONE = 0,
	DMH_COMMAND_REQUEST_COMMAND,
	DMH_COMMAND_REQUEST_INVALID_COMMAND,
	DMH_COMMAND_REQUEST_INVALID_ARGUMENT,
};

struct dmh_command_request {
	enum dmh_command_request_kind kind;
	struct dmh_command command;
};

struct dmh_command_ingress {
	struct dmh_ndjson_framer framer;
};

void dmh_command_ingress_init(struct dmh_command_ingress *ingress);
void dmh_command_ingress_reset(struct dmh_command_ingress *ingress);
int dmh_command_ingress_feed(
	struct dmh_command_ingress *ingress,
	const uint8_t *input,
	size_t input_length,
	struct dmh_command_request *request,
	size_t *consumed_bytes
);

#endif
```

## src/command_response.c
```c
#include "command_response.h"

#include <errno.h>
#include <stdbool.h>
#include <string.h>

struct response_writer {
	char *output;
	size_t capacity;
	size_t length;
};

static bool append_bytes(
	struct response_writer *writer,
	const char *bytes,
	size_t length
)
{
	if (length > writer->capacity - writer->length) {
		return false;
	}
	memcpy(writer->output + writer->length, bytes, length);
	writer->length += length;
	return true;
}

static bool append_literal(struct response_writer *writer, const char *literal)
{
	return append_bytes(writer, literal, strlen(literal));
}

static bool append_decimal(struct response_writer *writer, uint64_t value)
{
	char digits[20];
	size_t index = sizeof(digits);

	do {
		index--;
		digits[index] = (char)('0' + value % 10U);
		value /= 10U;
	} while (value > 0U);
	return append_bytes(writer, &digits[index], sizeof(digits) - index);
}

static bool valid_utf8_detail(const uint8_t *detail, size_t length)
{
	size_t index = 0U;

	while (index < length) {
		uint8_t first = detail[index++];

		if (first < 0x80U) {
			if (first < 0x20U || first == 0x7FU) {
				return false;
			}
			continue;
		}
		if (first >= 0xC2U && first <= 0xDFU) {
			if (index >= length || detail[index] < 0x80U ||
			    detail[index] > 0xBFU ||
			    (first == 0xC2U && detail[index] <= 0x9FU)) {
				return false;
			}
			index++;
			continue;
		}
		if (first >= 0xE0U && first <= 0xEFU) {
			if (index + 1U >= length || detail[index] < 0x80U ||
			    detail[index] > 0xBFU || detail[index + 1U] < 0x80U ||
			    detail[index + 1U] > 0xBFU ||
			    (first == 0xE0U && detail[index] < 0xA0U) ||
			    (first == 0xEDU && detail[index] > 0x9FU)) {
				return false;
			}
			index += 2U;
			continue;
		}
		if (first >= 0xF0U && first <= 0xF4U) {
			if (index + 2U >= length || detail[index] < 0x80U ||
			    detail[index] > 0xBFU || detail[index + 1U] < 0x80U ||
			    detail[index + 1U] > 0xBFU || detail[index + 2U] < 0x80U ||
			    detail[index + 2U] > 0xBFU ||
			    (first == 0xF0U && detail[index] < 0x90U) ||
			    (first == 0xF4U && detail[index] > 0x8FU)) {
				return false;
			}
			index += 3U;
			continue;
		}
		return false;
	}
	return true;
}

static bool append_json_string(
	struct response_writer *writer,
	const char *value,
	size_t length
)
{
	size_t index;

	for (index = 0U; index < length; index++) {
		if ((value[index] == '"' || value[index] == '\\') &&
		    !append_bytes(writer, "\\", 1U)) {
			return false;
		}
		if (!append_bytes(writer, &value[index], 1U)) {
			return false;
		}
	}
	return true;
}

static int finish_response(
	struct response_writer *writer,
	size_t *output_length
)
{
	if (!append_literal(writer, "}\n")) {
		return -ENOSPC;
	}
	*output_length = writer->length;
	return 0;
}

int dmh_success_response_encode(
	char *output,
	size_t output_capacity,
	size_t *output_length
)
{
	static const char frame[] = "{\"ok\":true}\n";

	if (output == NULL || output_length == NULL) {
		return -EINVAL;
	}
	if (sizeof(frame) - 1U > output_capacity) {
		return -ENOSPC;
	}
	memcpy(output, frame, sizeof(frame) - 1U);
	*output_length = sizeof(frame) - 1U;
	return 0;
}

int dmh_timestamp_response_encode(
	uint64_t timestamp_us,
	char *output,
	size_t output_capacity,
	size_t *output_length
)
{
	struct response_writer writer = {
		.output = output,
		.capacity = output_capacity,
	};

	if (output == NULL || output_length == NULL) {
		return -EINVAL;
	}
	if (!append_literal(&writer, "{\"ok\":true,\"timestamp_us\":") ||
	    !append_decimal(&writer, timestamp_us)) {
		return -ENOSPC;
	}
	return finish_response(&writer, output_length);
}

int dmh_uart_send_response_encode(
	uint64_t timestamp_us,
	size_t bytes_accepted,
	char *output,
	size_t output_capacity,
	size_t *output_length
)
{
	struct response_writer writer = {
		.output = output,
		.capacity = output_capacity,
	};

	if (output == NULL || output_length == NULL || bytes_accepted > 1024U) {
		return -EINVAL;
	}
	if (!append_literal(&writer, "{\"ok\":true,\"timestamp_us\":") ||
	    !append_decimal(&writer, timestamp_us) ||
	    !append_literal(&writer, ",\"bytes_accepted\":") ||
	    !append_decimal(&writer, bytes_accepted)) {
		return -ENOSPC;
	}
	return finish_response(&writer, output_length);
}

int dmh_error_response_encode(
	enum dmh_command_error_code code,
	const char *detail,
	size_t detail_length,
	char *output,
	size_t output_capacity,
	size_t *output_length
)
{
	static const char *const codes[] = {
		[DMH_COMMAND_ERROR_INVALID_COMMAND] = "invalid_command",
		[DMH_COMMAND_ERROR_INVALID_ARGUMENT] = "invalid_argument",
		[DMH_COMMAND_ERROR_NOT_CONFIGURED] = "not_configured",
		[DMH_COMMAND_ERROR_CAPTURE_ACTIVE] = "capture_active",
		[DMH_COMMAND_ERROR_HARDWARE_FAULT] = "hardware_fault",
		[DMH_COMMAND_ERROR_TIMEOUT] = "timeout",
	};
	struct response_writer writer = {
		.output = output,
		.capacity = output_capacity,
	};
	const char *code_name;

	if ((unsigned int)code >= sizeof(codes) / sizeof(codes[0]) ||
	    detail == NULL || detail_length == 0U ||
	    detail_length > DMH_COMMAND_ERROR_DETAIL_MAX_BYTES || output == NULL ||
	    output_length == NULL ||
	    !valid_utf8_detail((const uint8_t *)detail, detail_length)) {
		return -EINVAL;
	}
	code_name = codes[code];
	if (!append_literal(&writer, "{\"ok\":false,\"error\":\"") ||
	    !append_literal(&writer, code_name) ||
	    !append_literal(&writer, "\",\"detail\":\"") ||
	    !append_json_string(&writer, detail, detail_length) ||
	    !append_literal(&writer, "\"")) {
		return -ENOSPC;
	}
	return finish_response(&writer, output_length);
}
```

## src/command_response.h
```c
#ifndef DUTCHMATE_COMMAND_RESPONSE_H
#define DUTCHMATE_COMMAND_RESPONSE_H

#include <stddef.h>
#include <stdint.h>

#define DMH_COMMAND_RESPONSE_FRAME_CAPACITY 640U
#define DMH_COMMAND_ERROR_DETAIL_MAX_BYTES 256U

enum dmh_command_error_code {
	DMH_COMMAND_ERROR_INVALID_COMMAND = 0,
	DMH_COMMAND_ERROR_INVALID_ARGUMENT,
	DMH_COMMAND_ERROR_NOT_CONFIGURED,
	DMH_COMMAND_ERROR_CAPTURE_ACTIVE,
	DMH_COMMAND_ERROR_HARDWARE_FAULT,
	DMH_COMMAND_ERROR_TIMEOUT,
};

int dmh_success_response_encode(
	char *output,
	size_t output_capacity,
	size_t *output_length
);
int dmh_timestamp_response_encode(
	uint64_t timestamp_us,
	char *output,
	size_t output_capacity,
	size_t *output_length
);
int dmh_uart_send_response_encode(
	uint64_t timestamp_us,
	size_t bytes_accepted,
	char *output,
	size_t output_capacity,
	size_t *output_length
);
int dmh_error_response_encode(
	enum dmh_command_error_code code,
	const char *detail,
	size_t detail_length,
	char *output,
	size_t output_capacity,
	size_t *output_length
);

#endif
```
